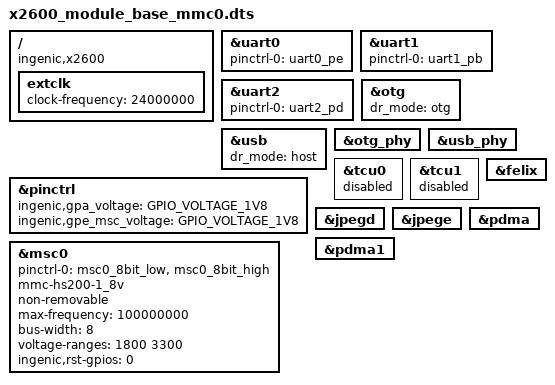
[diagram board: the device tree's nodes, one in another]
/dts-v1/;

#include <dt-bindings/input/input.h>
#include "x2600.dtsi"
#include <dt-bindings/interrupt-controller/irq.h>
#include <generated/autoconf.h>

/ {
	compatible = "ingenic,x2600";
	/*chosen {
		bootargs = "console=ttyS0,115200 mem=128M@0x0 ip=off init=/linuxrc ubi.mtd=2 root=ubi0:rootfs ubi.mtd=3 rootfstype=ubifs rw flashtype=nand";
	};*/

};

&uart0 {
	status = "okay";
	pinctrl-names = "default";
	pinctrl-0 = <&uart0_pe>;
};

&uart1 {
	status = "okay";
	pinctrl-names = "default";
	pinctrl-0 = <&uart1_pb>;
};

&uart2 {
	status = "okay";
	pinctrl-names = "default";
	pinctrl-0 = <&uart2_pd>;
};

&otg {
	dr_mode = "otg"; // host,peripheral,otg
	status = "okay";
};

&usb {
	dr_mode = "host"; // host,peripheral,otg
	status = "okay";
};

&otg_phy {
	status = "okay";
};

&usb_phy {
	status = "okay";
};

&pinctrl {
	ingenic,gpa_voltage = <GPIO_VOLTAGE_1V8>;
	ingenic,gpe_msc_voltage = <GPIO_VOLTAGE_1V8>;
};

&msc0 {
	status = "okay";
	pinctrl-names ="default";
	pinctrl-0 = <&msc0_8bit_low>,<&msc0_8bit_high>;
	mmc-hs200-1_8v;
	non-removable;
	max-frequency = <100000000>;
	bus-width = <8>;
	voltage-ranges = <1800 3300>;

	/* special property */
	ingenic,rst-gpios = <0>;
};

&tcu0 {
	status = "disable";
};

&tcu1 {
	status = "disable";
};

/ {

	extclk: extclk {
		clock-frequency = <24000000>;
	};
};

&jpegd {
    status = "okay";
};

&jpege {
    status = "okay";
};

&felix {
	status = "okay";
};

&pdma {
	status = "okay";
};

&pdma1 {
	status = "okay";
};


